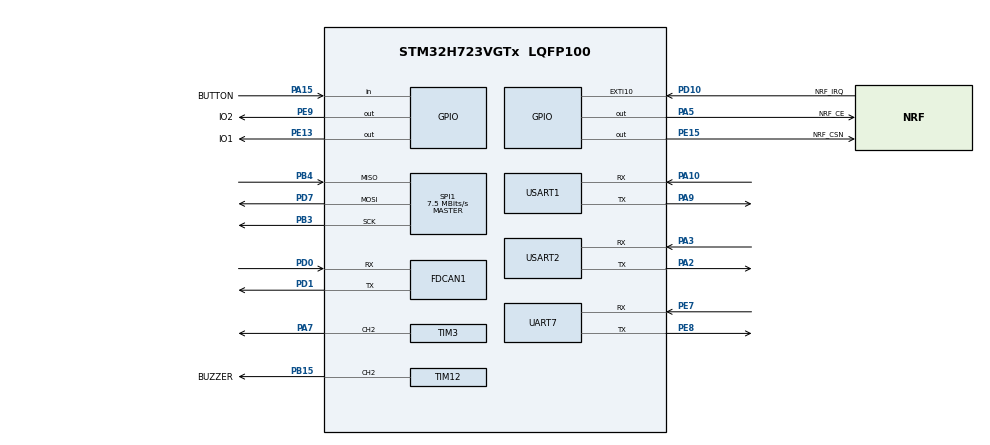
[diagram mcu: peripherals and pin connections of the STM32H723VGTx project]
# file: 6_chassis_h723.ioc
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CORTEX_M7.default_mode_Activation=1
Dma.Request0=USART1_RX
Dma.Request1=USART2_RX
Dma.Request2=TIM3_CH2
Dma.Request3=UART7_RX
Dma.TIM3_CH2.2.Direction=DMA_MEMORY_TO_PERIPH
Dma.TIM3_CH2.2.EventEnable=DISABLE
Dma.TIM3_CH2.2.FIFOMode=DMA_FIFOMODE_DISABLE
Dma.TIM3_CH2.2.Instance=DMA1_Stream2
Dma.TIM3_CH2.2.MemDataAlignment=DMA_MDATAALIGN_HALFWORD
Dma.TIM3_CH2.2.MemInc=DMA_MINC_ENABLE
Dma.TIM3_CH2.2.Mode=DMA_NORMAL
Dma.TIM3_CH2.2.PeriphDataAlignment=DMA_PDATAALIGN_HALFWORD
Dma.TIM3_CH2.2.PeriphInc=DMA_PINC_DISABLE
Dma.TIM3_CH2.2.Polarity=HAL_DMAMUX_REQ_GEN_RISING
Dma.TIM3_CH2.2.Priority=DMA_PRIORITY_HIGH
Dma.TIM3_CH2.2.RequestNumber=1
Dma.TIM3_CH2.2.SignalID=NONE
Dma.TIM3_CH2.2.SyncEnable=DISABLE
Dma.TIM3_CH2.2.SyncPolarity=HAL_DMAMUX_SYNC_NO_EVENT
Dma.TIM3_CH2.2.SyncRequestNumber=1
Dma.TIM3_CH2.2.SyncSignalID=NONE
Dma.UART7_RX.3.Direction=DMA_PERIPH_TO_MEMORY
Dma.UART7_RX.3.EventEnable=DISABLE
Dma.UART7_RX.3.FIFOMode=DMA_FIFOMODE_DISABLE
Dma.UART7_RX.3.Instance=DMA1_Stream3
Dma.UART7_RX.3.MemDataAlignment=DMA_MDATAALIGN_BYTE
Dma.UART7_RX.3.MemInc=DMA_MINC_ENABLE
Dma.UART7_RX.3.Mode=DMA_NORMAL
Dma.UART7_RX.3.PeriphDataAlignment=DMA_PDATAALIGN_BYTE
Dma.UART7_RX.3.PeriphInc=DMA_PINC_DISABLE
Dma.UART7_RX.3.Polarity=HAL_DMAMUX_REQ_GEN_RISING
Dma.UART7_RX.3.Priority=DMA_PRIORITY_HIGH
Dma.UART7_RX.3.RequestNumber=1
Dma.UART7_RX.3.SignalID=NONE
Dma.UART7_RX.3.SyncEnable=DISABLE
Dma.UART7_RX.3.SyncPolarity=HAL_DMAMUX_SYNC_NO_EVENT
Dma.UART7_RX.3.SyncRequestNumber=1
Dma.UART7_RX.3.SyncSignalID=NONE
Dma.USART1_RX.0.Direction=DMA_PERIPH_TO_MEMORY
Dma.USART1_RX.0.EventEnable=DISABLE
Dma.USART1_RX.0.FIFOMode=DMA_FIFOMODE_DISABLE
Dma.USART1_RX.0.Instance=DMA1_Stream0
Dma.USART1_RX.0.MemDataAlignment=DMA_MDATAALIGN_BYTE
Dma.USART1_RX.0.MemInc=DMA_MINC_ENABLE
Dma.USART1_RX.0.Mode=DMA_NORMAL
Dma.USART1_RX.0.PeriphDataAlignment=DMA_PDATAALIGN_BYTE
Dma.USART1_RX.0.PeriphInc=DMA_PINC_DISABLE
Dma.USART1_RX.0.Polarity=HAL_DMAMUX_REQ_GEN_RISING
Dma.USART1_RX.0.Priority=DMA_PRIORITY_HIGH
Dma.USART1_RX.0.RequestNumber=1
Dma.USART1_RX.0.SignalID=NONE
Dma.USART1_RX.0.SyncEnable=DISABLE
Dma.USART1_RX.0.SyncPolarity=HAL_DMAMUX_SYNC_NO_EVENT
Dma.USART1_RX.0.SyncRequestNumber=1
Dma.USART1_RX.0.SyncSignalID=NONE
Dma.USART2_RX.1.Direction=DMA_PERIPH_TO_MEMORY
Dma.USART2_RX.1.EventEnable=DISABLE
Dma.USART2_RX.1.FIFOMode=DMA_FIFOMODE_DISABLE
Dma.USART2_RX.1.Instance=DMA1_Stream1
Dma.USART2_RX.1.MemDataAlignment=DMA_MDATAALIGN_BYTE
Dma.USART2_RX.1.MemInc=DMA_MINC_ENABLE
Dma.USART2_RX.1.Mode=DMA_NORMAL
Dma.USART2_RX.1.PeriphDataAlignment=DMA_PDATAALIGN_BYTE
Dma.USART2_RX.1.PeriphInc=DMA_PINC_DISABLE
Dma.USART2_RX.1.Polarity=HAL_DMAMUX_REQ_GEN_RISING
Dma.USART2_RX.1.Priority=DMA_PRIORITY_HIGH
Dma.USART2_RX.1.RequestNumber=1
Dma.USART2_RX.1.SignalID=NONE
Dma.USART2_RX.1.SyncEnable=DISABLE
Dma.USART2_RX.1.SyncPolarity=HAL_DMAMUX_SYNC_NO_EVENT
Dma.USART2_RX.1.SyncRequestNumber=1
Dma.USART2_RX.1.SyncSignalID=NONE
FDCAN1.AutoRetransmission=ENABLE
FDCAN1.CalculateBaudRateNominal=1000000
FDCAN1.CalculateTimeBitNominal=1000
FDCAN1.CalculateTimeQuantumNominal=25.0
FDCAN1.DataSyncJumpWidth=10
FDCAN1.DataTimeSeg1=29
FDCAN1.DataTimeSeg2=10
FDCAN1.NominalPrescaler=3
FDCAN1.NominalSyncJumpWidth=10
FDCAN1.NominalTimeSeg1=29
FDCAN1.NominalTimeSeg2=10
FDCAN1.RxFifo0ElmtsNbr=64
FDCAN1.StdFiltersNbr=16
FDCAN1.TxFifoQueueElmtsNbr=32
FREERTOS.BinarySemaphores01=NrflrqSem,Dynamic,NULL,Available
FREERTOS.Tasks01=SerialTxTask,24,1024,StartSerialTxTask,As weak,NULL,Dynamic,NULL,NULL;SerialCmdTask,32,512,StartSerialCmdTask,As weak,NULL,Dynamic,NULL,NULL;NrfCmdTask,37,1024,StartNrfCmdTask,As weak,NULL,Dynamic,NULL,NULL;VisionCmdTask,39,512,StartVisionCmdTask,As weak,NULL,Dynamic,NULL,NULL;MotorCtlTask,40,512,StartMotorCtlTask,As weak,NULL,Dynamic,NULL,NULL
Mcu.Family=STM32H7
Mcu.Name=STM32H723VGTx
Mcu.Package=LQFP100
NVIC.DMA1_Stream0_IRQn=true\:5\:0\:false\:false\:true\:true\:false\:true\:true
NVIC.DMA1_Stream1_IRQn=true\:5\:0\:false\:false\:true\:true\:false\:true\:true
NVIC.DMA1_Stream2_IRQn=true\:5\:0\:false\:false\:true\:true\:false\:true\:true
NVIC.DMA1_Stream3_IRQn=true\:5\:0\:false\:false\:true\:true\:false\:true\:true
NVIC.FDCAN1_IT0_IRQn=true\:5\:0\:false\:false\:true\:true\:true\:true\:true
NVIC.PriorityGroup=NVIC_PRIORITYGROUP_4
NVIC.SPI1_IRQn=true\:5\:0\:false\:false\:true\:true\:true\:true\:true
NVIC.TIM6_DAC_IRQn=true\:15\:0\:false\:false\:true\:false\:false\:true\:true
NVIC.TimeBase=TIM6_DAC_IRQn
NVIC.TimeBaseIP=TIM6
NVIC.UART7_IRQn=true\:5\:0\:false\:false\:true\:true\:true\:true\:true
NVIC.USART1_IRQn=true\:5\:0\:false\:false\:true\:true\:true\:true\:true
NVIC.USART2_IRQn=true\:5\:0\:false\:false\:true\:true\:true\:true\:true
PA10.Mode=Asynchronous
PA10.Signal=USART1_RX
PA13(JTMS/SWDIO).Mode=Serial_Wire
PA13(JTMS/SWDIO).Signal=DEBUG_JTMS-SWDIO
PA14(JTCK/SWCLK).Mode=Serial_Wire
PA14(JTCK/SWCLK).Signal=DEBUG_JTCK-SWCLK
PA15(JTDI).GPIO_Label=BUTTON
PA15(JTDI).GPIO_PuPd=GPIO_PULLUP
PA15(JTDI).Signal=GPIO_Input
PA2.Mode=Asynchronous
PA2.Signal=USART2_TX
PA3.Mode=Asynchronous
PA3.Signal=USART2_RX
PA5.GPIO_Label=NRF_CE
PA5.GPIO_PuPd=GPIO_PULLDOWN
PA5.Signal=GPIO_Output
PA7.Signal=S_TIM3_CH2
PA9.Mode=Asynchronous
PA9.Signal=USART1_TX
PB15.GPIO_Label=BUZZER
PB15.Signal=S_TIM12_CH2
PB3(JTDO/TRACESWO).GPIO_Speed=GPIO_SPEED_FREQ_HIGH
PB3(JTDO/TRACESWO).Mode=Full_Duplex_Master
PB3(JTDO/TRACESWO).Signal=SPI1_SCK
PB4(NJTRST).GPIO_Speed=GPIO_SPEED_FREQ_HIGH
PB4(NJTRST).Mode=Full_Duplex_Master
PB4(NJTRST).Signal=SPI1_MISO
PD0.Mode=FDCAN_Activate
PD0.Signal=FDCAN1_RX
PD1.Mode=FDCAN_Activate
PD1.Signal=FDCAN1_TX
PD10.GPIO_Label=NRF_IRQ
PD10.Signal=GPXTI10
PD7.GPIO_Speed=GPIO_SPEED_FREQ_HIGH
PD7.Mode=Full_Duplex_Master
PD7.Signal=SPI1_MOSI
PE13.GPIO_Label=IO1
PE13.GPIO_PuPd=GPIO_PULLDOWN
PE13.Signal=GPIO_Output
PE15.GPIO_Label=NRF_CSN
PE15.GPIO_PuPd=GPIO_PULLDOWN
PE15.Signal=GPIO_Output
PE7.Mode=Asynchronous
PE7.Signal=UART7_RX
PE8.Mode=Asynchronous
PE8.Signal=UART7_TX
PE9.GPIO_Label=IO2
PE9.GPIO_PuPd=GPIO_PULLDOWN
PE9.Signal=GPIO_Output
PH0-OSC_IN.Mode=HSE-External-Oscillator
PH0-OSC_IN.Signal=RCC_OSC_IN
PH1-OSC_OUT.Mode=HSE-External-Oscillator
PH1-OSC_OUT.Signal=RCC_OSC_OUT
ProjectManager.HeapSize=0x200
ProjectManager.StackSize=0x400
ProjectManager.TargetToolchain=CMake
RCC.ADCFreq_Value=48375000
RCC.APB1Freq_Value=120000000
RCC.APB2Freq_Value=120000000
RCC.APB3Freq_Value=120000000
RCC.APB4Freq_Value=120000000
RCC.CortexFreq_Value=240000000
RCC.D1PPRE=RCC_APB3_DIV2
RCC.D2PPRE1=RCC_APB1_DIV2
RCC.D2PPRE2=RCC_APB2_DIV2
RCC.D3PPRE=RCC_APB4_DIV2
RCC.DIVM1=2
RCC.DIVN1=20
RCC.DIVP1=1
RCC.EnbaleCSS=true
RCC.HCLKFreq_Value=240000000
RCC.HSE_VALUE=24000000
RCC.PLL2FRACN=0
RCC.PLL3FRACN=0
RCC.PLLFRACN=0
RCC.PLLSourceVirtual=RCC_PLLSOURCE_HSE
RCC.SYSCLKFreq_VALUE=240000000
RCC.SYSCLKSource=RCC_SYSCLKSOURCE_PLLCLK
RCC.USBFreq_Value=120000000
SH.S_TIM12_CH2.0=TIM12_CH2,PWM Generation2 CH2
SH.S_TIM3_CH2.0=TIM3_CH2,PWM Generation2 CH2
SPI1.BaudRatePrescaler=SPI_BAUDRATEPRESCALER_16
SPI1.CalculateBaudRate=7.5 MBits/s
SPI1.DataSize=SPI_DATASIZE_8BIT
SPI1.Direction=SPI_DIRECTION_2LINES
SPI1.Mode=SPI_MODE_MASTER
SPI1.VirtualType=VM_MASTER
TIM12.AutoReloadPreload=TIM_AUTORELOAD_PRELOAD_ENABLE
TIM12.Channel-PWM\ Generation2\ CH2=TIM_CHANNEL_2
TIM12.Period=10
TIM12.Prescaler=24
TIM3.AutoReloadPreload=TIM_AUTORELOAD_PRELOAD_ENABLE
TIM3.Channel-PWM\ Generation2\ CH2=TIM_CHANNEL_2
TIM3.Period=149
TIM3.Prescaler=1
USART1.VirtualMode-Asynchronous=VM_ASYNC
USART2.VirtualMode-Asynchronous=VM_ASYNC
VP_FREERTOS_VS_CMSIS_V2.Mode=CMSIS_V2
VP_MEMORYMAP_VS_MEMORYMAP.Mode=CurAppReg
VP_SYS_VS_tim6.Mode=TIM6
VP_TIM12_VS_ClockSourceINT.Mode=Internal
VP_TIM3_VS_ClockSourceINT.Mode=Internal
board=custom

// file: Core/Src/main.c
/* USER CODE BEGIN Header */
/**
  ******************************************************************************
  * @file           : main.c
  * @brief          : Main program body
  ******************************************************************************
  * @attention
  *
  * Copyright (c) 2026 STMicroelectronics.
  * All rights reserved.
  *
  * This software is licensed under terms that can be found in the LICENSE file
  * in the root directory of this software component.
  * If no LICENSE file comes with this software, it is provided AS-IS.
  *
  ******************************************************************************
  */
/* USER CODE END Header */
#include "main.h"
#include "FreeRTOS.h"
#include "cmsis_os2.h"
#include "dma.h"
#include "fdcan.h"
#include "spi.h"
#include "tim.h"
#include "usart.h"
#include "gpio.h"

/* USER CODE BEGIN Includes */
#include "string.h"
/* USER CODE END Includes */

void SystemClock_Config(void);
static void MPU_Config(void);
void MX_FREERTOS_Init(void);

int main(void)
{

  /* MPU Configuration--------------------------------------------------------*/
  MPU_Config();

  /* MCU Configuration--------------------------------------------------------*/

  /* Reset of all peripherals, Initializes the Flash interface and the Systick. */
  HAL_Init();

  /* Configure the system clock */
  SystemClock_Config();

  /* Initialize all configured peripherals */
  MX_GPIO_Init();
  MX_DMA_Init();
  MX_USART1_UART_Init();
  MX_TIM3_Init();
  MX_USART2_UART_Init();
  MX_FDCAN1_Init();
  MX_UART7_Init();
  MX_TIM12_Init();
  MX_SPI1_Init();

  /* Init scheduler */
  osKernelInitialize();  /* Call init function for freertos objects (in cmsis_os2.c) */
  MX_FREERTOS_Init();

  /* Start scheduler */
  osKernelStart();

  /* We should never get here as control is now taken by the scheduler */

  /* Infinite loop */
  while (1)
  {

  }
}

void SystemClock_Config(void)
{
  RCC_OscInitTypeDef RCC_OscInitStruct = {0};
  RCC_ClkInitTypeDef RCC_ClkInitStruct = {0};

  /** Supply configuration update enable
  */
  HAL_PWREx_ConfigSupply(PWR_LDO_SUPPLY);

  /** Configure the main internal regulator output voltage
  */
  __HAL_PWR_VOLTAGESCALING_CONFIG(PWR_REGULATOR_VOLTAGE_SCALE0);

  while(!__HAL_PWR_GET_FLAG(PWR_FLAG_VOSRDY)) {}

  /** Initializes the RCC Oscillators according to the specified parameters
  * in the RCC_OscInitTypeDef structure.
  */
  RCC_OscInitStruct.OscillatorType = RCC_OSCILLATORTYPE_HSE;
  RCC_OscInitStruct.HSEState = RCC_HSE_ON;
  RCC_OscInitStruct.PLL.PLLState = RCC_PLL_ON;
  RCC_OscInitStruct.PLL.PLLSource = RCC_PLLSOURCE_HSE;
  RCC_OscInitStruct.PLL.PLLM = 2;
  RCC_OscInitStruct.PLL.PLLN = 20;
  RCC_OscInitStruct.PLL.PLLP = 1;
  RCC_OscInitStruct.PLL.PLLQ = 2;
  RCC_OscInitStruct.PLL.PLLR = 2;
  RCC_OscInitStruct.PLL.PLLRGE = RCC_PLL1VCIRANGE_3;
  RCC_OscInitStruct.PLL.PLLVCOSEL = RCC_PLL1VCOWIDE;
  RCC_OscInitStruct.PLL.PLLFRACN = 0;
  if (HAL_RCC_OscConfig(&RCC_OscInitStruct) != HAL_OK)
  {
    Error_Handler();
  }

  /** Initializes the CPU, AHB and APB buses clocks
  */
  RCC_ClkInitStruct.ClockType = RCC_CLOCKTYPE_HCLK|RCC_CLOCKTYPE_SYSCLK
                              |RCC_CLOCKTYPE_PCLK1|RCC_CLOCKTYPE_PCLK2
                              |RCC_CLOCKTYPE_D3PCLK1|RCC_CLOCKTYPE_D1PCLK1;
  RCC_ClkInitStruct.SYSCLKSource = RCC_SYSCLKSOURCE_PLLCLK;
  RCC_ClkInitStruct.SYSCLKDivider = RCC_SYSCLK_DIV1;
  RCC_ClkInitStruct.AHBCLKDivider = RCC_HCLK_DIV1;
  RCC_ClkInitStruct.APB3CLKDivider = RCC_APB3_DIV2;
  RCC_ClkInitStruct.APB1CLKDivider = RCC_APB1_DIV2;
  RCC_ClkInitStruct.APB2CLKDivider = RCC_APB2_DIV2;
  RCC_ClkInitStruct.APB4CLKDivider = RCC_APB4_DIV2;

  if (HAL_RCC_ClockConfig(&RCC_ClkInitStruct, FLASH_LATENCY_3) != HAL_OK)
  {
    Error_Handler();
  }

  /** Enables the Clock Security System
  */
  HAL_RCC_EnableCSS();
}

 /* MPU Configuration */

void MPU_Config(void)
{
  MPU_Region_InitTypeDef MPU_InitStruct = {0};

  /* Disables the MPU */
  HAL_MPU_Disable();

  /** Initializes and configures the Region and the memory to be protected
  */
  MPU_InitStruct.Enable = MPU_REGION_ENABLE;
  MPU_InitStruct.Number = MPU_REGION_NUMBER0;
  MPU_InitStruct.BaseAddress = 0x0;
  MPU_InitStruct.Size = MPU_REGION_SIZE_4GB;
  MPU_InitStruct.SubRegionDisable = 0x87;
  MPU_InitStruct.TypeExtField = MPU_TEX_LEVEL0;
  MPU_InitStruct.AccessPermission = MPU_REGION_NO_ACCESS;
  MPU_InitStruct.DisableExec = MPU_INSTRUCTION_ACCESS_DISABLE;
  MPU_InitStruct.IsShareable = MPU_ACCESS_SHAREABLE;
  MPU_InitStruct.IsCacheable = MPU_ACCESS_NOT_CACHEABLE;
  MPU_InitStruct.IsBufferable = MPU_ACCESS_NOT_BUFFERABLE;

  HAL_MPU_ConfigRegion(&MPU_InitStruct);
  /* Enables the MPU */
  HAL_MPU_Enable(MPU_PRIVILEGED_DEFAULT);

}

void HAL_TIM_PeriodElapsedCallback(TIM_HandleTypeDef *htim)
{
  if (htim->Instance == TIM6)
  {
    HAL_IncTick();
  }
}

void Error_Handler(void)
{
  __disable_irq();
  while (1)
  {
  }
}

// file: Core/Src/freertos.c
/* USER CODE BEGIN Header */
/**
  ******************************************************************************
  * File Name          : freertos.c
  * Description        : Code for freertos applications
  ******************************************************************************
  * @attention
  *
  * Copyright (c) 2026 STMicroelectronics.
  * All rights reserved.
  *
  * This software is licensed under terms that can be found in the LICENSE file
  * in the root directory of this software component.
  * If no LICENSE file comes with this software, it is provided AS-IS.
  *
  ******************************************************************************
  */
/* USER CODE END Header */

#include "FreeRTOS.h"
#include "task.h"
#include "main.h"
#include "FreeRTOS.h"
#include "cmsis_os2.h"

/* Definitions for SerialTxTask */
osThreadId_t SerialTxTaskHandle;
const osThreadAttr_t SerialTxTask_attributes = {
  .name = "SerialTxTask",
  .stack_size = 1024 * 4,
  .priority = (osPriority_t) osPriorityNormal,
};
/* Definitions for SerialCmdTask */
osThreadId_t SerialCmdTaskHandle;
const osThreadAttr_t SerialCmdTask_attributes = {
  .name = "SerialCmdTask",
  .stack_size = 512 * 4,
  .priority = (osPriority_t) osPriorityAboveNormal,
};
/* Definitions for NrfCmdTask */
osThreadId_t NrfCmdTaskHandle;
const osThreadAttr_t NrfCmdTask_attributes = {
  .name = "NrfCmdTask",
  .stack_size = 1024 * 4,
  .priority = (osPriority_t) osPriorityAboveNormal5,
};
/* Definitions for VisionCmdTask */
osThreadId_t VisionCmdTaskHandle;
const osThreadAttr_t VisionCmdTask_attributes = {
  .name = "VisionCmdTask",
  .stack_size = 512 * 4,
  .priority = (osPriority_t) osPriorityAboveNormal7,
};
/* Definitions for MotorCtlTask */
osThreadId_t MotorCtlTaskHandle;
const osThreadAttr_t MotorCtlTask_attributes = {
  .name = "MotorCtlTask",
  .stack_size = 512 * 4,
  .priority = (osPriority_t) osPriorityHigh,
};
/* Definitions for NrflrqSem */
osSemaphoreId_t NrflrqSemHandle;
const osSemaphoreAttr_t NrflrqSem_attributes = {
  .name = "NrflrqSem"
};

void StartSerialTxTask(void *argument);
void StartSerialCmdTask(void *argument);
void StartNrfCmdTask(void *argument);
void StartVisionCmdTask(void *argument);
void StartMotorCtlTask(void *argument);

void MX_FREERTOS_Init(void); /* (MISRA C 2004 rule 8.1) */

void MX_FREERTOS_Init(void) {

  /* Create the semaphores(s) */
  /* creation of NrflrqSem */
  NrflrqSemHandle = osSemaphoreNew(1, 1, &NrflrqSem_attributes);

  /* Create the thread(s) */
  /* creation of SerialTxTask */
  SerialTxTaskHandle = osThreadNew(StartSerialTxTask, NULL, &SerialTxTask_attributes);

  /* creation of SerialCmdTask */
  SerialCmdTaskHandle = osThreadNew(StartSerialCmdTask, NULL, &SerialCmdTask_attributes);

  /* creation of NrfCmdTask */
  NrfCmdTaskHandle = osThreadNew(StartNrfCmdTask, NULL, &NrfCmdTask_attributes);

  /* creation of VisionCmdTask */
  VisionCmdTaskHandle = osThreadNew(StartVisionCmdTask, NULL, &VisionCmdTask_attributes);

  /* creation of MotorCtlTask */
  MotorCtlTaskHandle = osThreadNew(StartMotorCtlTask, NULL, &MotorCtlTask_attributes);

}

__weak void StartSerialTxTask(void *argument)
{
  for(;;)
  {
    osDelay(1);
  }
}

__weak void StartSerialCmdTask(void *argument)
{
  for(;;)
  {
    osDelay(1);
  }
}

__weak void StartNrfCmdTask(void *argument)
{
  for(;;)
  {
    osDelay(1);
  }
}

__weak void StartVisionCmdTask(void *argument)
{
  for(;;)
  {
    osDelay(1);
  }
}

__weak void StartMotorCtlTask(void *argument)
{
  for(;;)
  {
    osDelay(1);
  }
}
